# M051DE_v1 register map
File version: 1.0
Registers are 32-bit, read-write, reset 0x0 unless marked. A register's access mark holds for its fields unless they carry their own. Offsets are from the block's base; [hi:lo] are bit positions; lines under a group give offsets from that group; {n}, {i} and the like mark numbered series; 'fields as' and 'values as' point back to an identical list.

## PWMA — PWM Register Map
Base 0x40040000
Same registers: PWMB 0x40140000
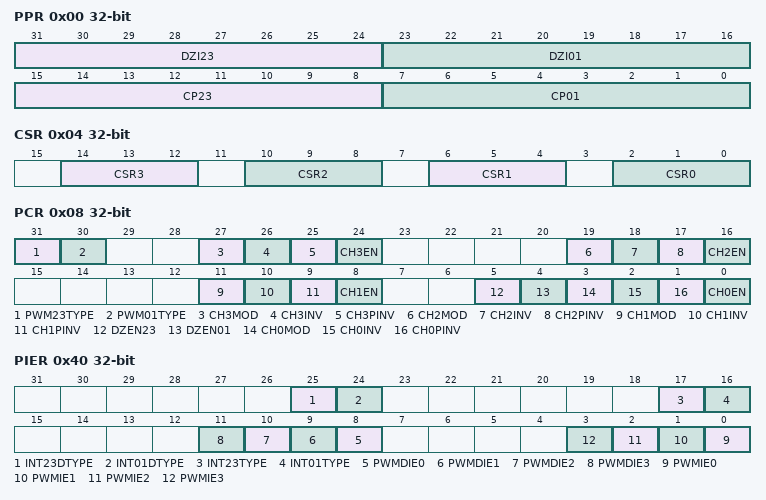
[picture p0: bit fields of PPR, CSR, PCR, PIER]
0x00 PPR — PWM Prescaler Register
  [31:24] DZI23 — Dead-zone Interval for Pair of Channel 2 and Channel 3 (PWM2 and PWM3 Pair for PWM Group A, PWM6 and PWM7 Pair for PWM Group B). These 8-bit determine the Dead-zone length.
  [23:16] DZI01 — Dead-zone Interval for Pair of Channel 0 and Channel 1 (PWM0 and PWM1 Pair for PWM Group A, PWM4 and PWM5 Pair for PWM Group B). These 8-bit determine the Dead-zone length.
  [15:8] CP23 — Clock Prescaler 2 (PWM-timer 2 / 3 for Group A and PWM-timer 6 / 7 for Group B). Clock input is divided by (CP23 + 1) before it is fed to the corresponding PWM-Timer.
  [7:0] CP01 — Clock Prescaler 0 (PWM-timer 0 / 1 for Group A and PWM-timer 4 / 5 for Group B). Clock input is divided by (CP01 + 1) before it is fed to the corresponding PWM-Timer
0x04 CSR — PWM Clock Source Divider Select Register
  [14:12] CSR3 — PWM Timer 3 Clock Source Divider Selection (PWM Timer 3 for Group A and PWM Timer 7 for Group B)
  [10:8] CSR2 — PWM Timer 2 Clock Source Divider Selection (PWM Timer 2 for Group A and PWM Timer 6 for Group B). Select clock source divider for PWM timer 2. (Table is the same as CSR3)
  [6:4] CSR1 — PWM Timer 1 Clock Source Divider Selection (PWM Timer 1 for Group A and PWM Timer 5 for Group B). Select clock source divider for PWM timer 1. (Table is the same as CSR3)
  [2:0] CSR0 — PWM Timer 0 Clock Source Divider Selection (PWM Timer 0 for Group A and PWM Timer 4 for Group B). Select clock source divider for PWM timer 0. (Table is the same as CSR3)
0x08 PCR — PWM Control Register
  [31] PWM23TYPE — PWM23 Aligned Type Selection Bit (PWM2 and PWM3 Pair for PWM Group A, PWM6 and PWM7 Pair for PWM Group B) (M05xxDN/DE Only)
    0=Edge-aligned type; 1=Center-aligned type
  [30] PWM01TYPE — PWM01 Aligned Type Selection Bit (PWM0 and PWM1 Pair for PWM Group A, PWM4 and PWM5 Pair for PWM Group B) (M05xxDN/DE Only)
    0=Edge-aligned type; 1=Center-aligned type
  [27] CH3MOD — PWM-timer 3 Auto-reload/One-shot Mode Control (PWM Timer 3 for Group A and PWM Timer 7 for Group B). Note: If there is a transition at this bit, it will cause CNR3 and CMR3 be cleared.
    0=One-shot mode; 1=Auto-reload mode
  [26] CH3INV — PWM-timer 3 Output Inverter Enable Control (PWM Timer 3 for Group A and PWM Timer 7 for Group B)
    0=Inverter Disabled; 1=Inverter Enabled
  [25] CH3PINV — PWM-timer 3 Output Polar Inverse Enable Control (PWM Timer 3 for Group A and PWM Timer 7 for Group B) (M05xxDN/DE Only)
    0=Polar Inverter Disabled; 1=Polar Inverter Enabled
  [24] CH3EN — PWM-timer 3 Enable Control (PWM Timer 3 for Group A and PWM Timer 7 for Group B)
    0=Corresponding PWM-Timer Stopped; 1=Corresponding PWM-Timer Start Running
  [19] CH2MOD — PWM-timer 2 Auto-reload/One-shot Mode Control (PWM Timer 2 for Group A and PWM Timer 6 for Group B). Note: If there is a transition at this bit, it will cause CNR2 and CMR2 be cleared.
    0=One-shot mode; 1=Auto-reload mode
  [18] CH2INV — PWM-timer 2 Output Inverter Enable Control (PWM Timer 2 for Group A and PWM Timer 6 for Group B)
    0=Inverter Disabled; 1=Inverter Enabled
  [17] CH2PINV — PWM-timer 2 Output Polar Inverse Enable (PWM Timer 2 for Group A and PWM Timer 6 for Group B) (M05xxDN/DE Only)
    0=Polar Inverter Disabled; 1=Polar Inverter Enabled
  [16] CH2EN — PWM-timer 2 Enable (PWM Timer 2 for Group A and PWM Timer 6 for Group B)
    values as CH3EN
  [11] CH1MOD — PWM-timer 1 Auto-reload/One-shot Mode (PWM Timer 1 for Group A and PWM Timer 5 for Group B). Note: If there is a transition at this bit, it will cause CNR1 and CMR1 be cleared.
    0=One-shot mode; 1=Auto-reload mode
  [10] CH1INV — PWM-timer 1 Output Inverter Enable (PWM Timer 1 for Group A and PWM Timer 5 for Group B)
    0=Inverter Disabled; 1=Inverter Enabled
  [9] CH1PINV — PWM-timer 1 Output Polar Inverse Enable (PWM Timer 1 for Group A and PWM Timer 5 for Group B) (M05xxDN/DE Only)
    0=Polar Inverter Disabled; 1=Polar Inverter Enabled
  [8] CH1EN — PWM-timer 1 Enable (PWM Timer 1 for Group A and PWM Timer 5 for Group B)
    values as CH3EN
  [5] DZEN23 — Dead-zone 2 Generator Enable (PWM2 and PWM3 Pair for PWM Group A, PWM6 and PWM7 Pair for PWM Group B). Note: When Dead-zone generator is enabled, the pair of PWM2 and PWM3 becomes a complementary pair for PWM group A and the pair of PWM6 and PWM7 becomes a complementary pair for PWM group B.
    0=Disabled; 1=Enabled
  [4] DZEN01 — Dead-zone 0 Generator Enable Control (PWM0 and PWM1 Pair for PWM Group A, PWM4 and PWM5 Pair for PWM Group B). Note: When Dead-zone generator is enabled, the pair of PWM0 and PWM1 becomes a complementary pair for PWM group A and the pair of PWM4 and PWM5 becomes a complementary pair for PWM group B.
    0=Disabled; 1=Enabled
  [3] CH0MOD — PWM-timer 0 Auto-reload/One-shot Mode Control (PWM Timer 0 for Group A and PWM Timer 4 for Group B). Note: If there is a transition at this bit, it will cause CNR0 and CMR0 be cleared.
    0=One-shot mode; 1=Auto-reload mode
  [2] CH0INV — PWM-timer 0 Output Inverter Enable Control (PWM Timer 0 for Group A and PWM Timer 4 for Group B)
    0=Inverter Disabled; 1=Inverter Enabled
  [1] CH0PINV — PWM-timer 0 Output Polar Inverse Enable Control (PWM Timer 0 for Group A and PWM Timer 4 for Group B) (M05xxDN/DE Only)
    0=Polar Inverter Disabled; 1=Polar Inverter Enabled
  [0] CH0EN — PWM-timer 0 Enable Control (PWM Timer 0 for Group A and PWM Timer 4 for Group B)
    0=The corresponding PWM-Timer stops running; 1=The corresponding PWM-Timer starts running
{0xC+0xC*i} CNR{i} (i=0..3) — PWM Counter Register {i}
  [15:0] CNRx — PWM Timer Loaded Value. CNR determines the PWM period. Note1: Any write operation to CNR will take effect in next PWM cycle. Note2: When CNR value is set to 0, PWM output is always high. Note3: When PWM operating at center-aligned type, CNR value should be set between 0x0001 to 0xFFFE. If CNR equal to 0x0000 or 0xFFFF, the PWM will work unpredictable.
{0x10+0xC*i} CMR{i} (i=0..3) — PWM Comparator Register {i}
  [15:0] CMRx — PWM Comparator Register. CMR determines the PWM duty. Note: Any write operation to CMR will take effect in next PWM cycle.
{0x14+0xC*i} PDR{i} ro (i=0..3) — PWM Data Register {i}
  [15:0] PDRx — PWM Data Register. User can monitor PDR to know the current value in 16-bit counter.
0x40 PIER — PWM Interrupt Enable Register
  [25] INT23DTYPE — PWM23 Duty Interrupt Type Selection (PWM2 and PWM3 Pair for PWM Group A, PWM6 and PWM7 Pair for PWM Group B) (M05xxDN/DE Only). Note: Set INT23DTYPE to 1 only work when PWM operating in center aligned type.
    0=PWMDIFx will be set if PWM counter down count and matches CMRx register. PWM will trigger ADC to conversion when PWM counter down count and matches CMRx register if correlate PWM trigger enable bit (PWMxDTEN) is set to 1; 1=PWMDIFx will be set when PWM counter up count and matches CMRx register. PWM will trigger ADC to conversion when PWM counter up count and matches CMRx register if correlate PWM trigger enable bit (PWMxDTEN) is set to 1
  [24] INT01DTYPE — PWM01 Duty Interrupt Type Selection (PWM0 and PWM1 Pair for PWM Group A, PWM4 and PWM5 Pair for PWM Group B) (M05xxDN/DE Only). Note: Set INT01DTYPE to 1 only work when PWM operating in center aligned type.
    values as INT23DTYPE
  [17] INT23TYPE — PWM23 Interrupt Period Type Selection (PWM2 and PWM3 Pair for PWM Group A, PWM6 and PWM7 Pair for PWM Group B) (M05xxDN/DE Only). Note: Setting INT23TYPE to 1 only works when PWM operating is in center-aligned type.
    0=PWMIFx will be set if PWM counter underflow. PWM will trigger ADC to conversion when PWM counter underflow if correlate PWM trigger enable bit (PWMxTEN) is set to 1; 1=PWMIFx will be set if PWM counter matches CNRx register. PWM will trigger ADC to conversion when PWM counter matches CNRx register if correlate PWM trigger enable bit (PWMxTEN) is set to 1
  [16] INT01TYPE — PWM01 Interrupt Period Type Selection (PWM0 and PWM1 Pair for PWM Group A, PWM4 and PWM5 Pair for PWM Group B) (M05xxDN/DE Only). Note: Setting INT01TYPE to 1 only works when PWM operating is in center-aligned type.
    values as INT23TYPE
  [n+8] PWMDIE{n} (n=0..3) — PWM Channel {n} Duty Interrupt Enable Control (M05xxDN/DE Only)
    0=PWM channel {n} duty interrupt Disabled; 1=PWM channel {n} duty interrupt Enabled
  [n] PWMIE{n} (n=0..3) — PWM Channel {n} Period Interrupt Enable Control
    0=PWM channel {n} period interrupt Disabled; 1=PWM channel {n} period interrupt Enabled
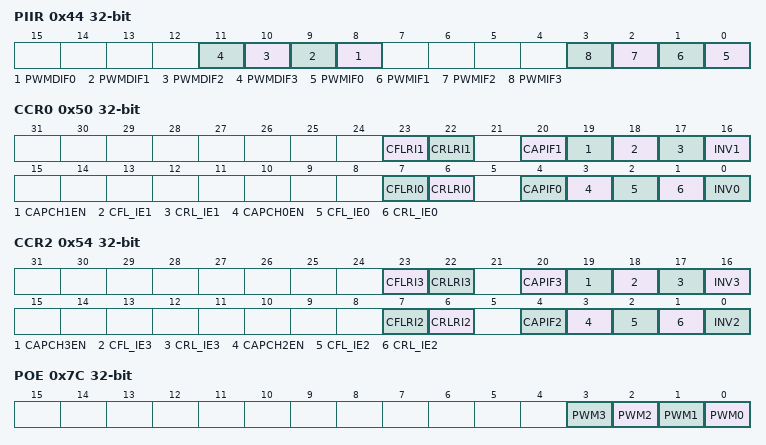
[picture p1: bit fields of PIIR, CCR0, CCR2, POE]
0x44 PIIR — PWM Interrupt Indication Register
  [n+8] PWMDIF{n} (n=0..3) — PWM Channel {n} Duty Interrupt Status (M05xxDN/DE Only). Note: Write 1 to clear this bit to 0.
  [n] PWMIF{n} (n=0..3) — PWM Channel {n} Period Interrupt Status. On M05xxBN: This bit is set by hardware when channel {n} PWM counter equal to zero if channel {n} PWM period interrupt enable bit (PWMIE{n}) is 1. Software can write 1 to clear this bit to 0. On M05xxDN/DE: Note: Write 1 to clear this bit to 0.
0x50 CCR0 — PWM Capture Control Register 0
  [23] CFLRI1 — CFLR1 Latched Indicator. When PWM group input channel 1 has a falling transition, CFLR1 was latched with the value of PWM down-counter and this bit is set by hardware. Note: Write 1 to clear this bit to 0.
  [22] CRLRI1 — CRLR1 Latched Indicator. When PWM group input channel 1 has a rising transition, CRLR1 was latched with the value of PWM down-counter and this bit is set by hardware. Note: Write 1 to clear this bit to 0.
  [20] CAPIF1 — Channel 1 Capture Interrupt Indication Flag. Note: Write 1 to clear this bit to 0.
  [19] CAPCH1EN — Channel 1 Capture Function Enable Control. Note1: When Enabled, Capture latched the PWM-counter and saved to CRLR (Rising latch) and CFLR (Falling latch). Note2: When Disabled, Capture does not update CRLR and CFLR, and disable PWM group channel 1 Interrupt.
    0=Capture function on PWM group channel 1 Disabled; 1=Capture function on PWM group channel 1 Enabled
  [18] CFL_IE1 — Channel 1 Falling Latch Interrupt Enable Control. Note: When Enabled, if Capture detects PWM group channel 1 has falling transition, Capture will issue an Interrupt.
    0=Falling latch interrupt Disabled; 1=Falling latch interrupt Enabled
  [17] CRL_IE1 — Channel 1 Rising Latch Interrupt Enable Control. Note: When Enabled, if Capture detects PWM group channel 1 has rising transition, Capture will issue an Interrupt.
    0=Rising latch interrupt Disabled; 1=Rising latch interrupt Enabled
  [16] INV1 — Capture Channel 1 Inverter Enable Control
    0=Inverter Disabled; 1=Inverter Enabled. Reverse the input signal from GPIO before fed to Capture timer
  [7] CFLRI0 — CFLR0 Latched Indicator Control. When PWM group input channel 0 has a falling transition, CFLR0 was latched with the value of PWM down-counter and this bit is set by hardware. Note: Write 1 to clear this bit to 0.
  [6] CRLRI0 — CRLR0 Latched Indicator. When PWM group input channel 0 has a rising transition, CRLR0 was latched with the value of PWM down-counter and this bit is set by hardware. Note: Write 1 to clear this bit to 0.
  [4] CAPIF0 — Channel 0 Capture Interrupt Indication Flag. Note: Write 1 to clear this bit to 0.
  [3] CAPCH0EN — Channel 0 Capture Function Enable Control. Note1: When Enabled, Capture latches the PWM-counter value and saved to CRLR (Rising latch) and CFLR (Falling latch). Note2: When Disabled, Capture does not update CRLR and CFLR, and disable PWM group channel 0 Interrupt.
    0=Capture function on PWM group channel 0 Disabled; 1=Capture function on PWM group channel 0 Enabled
  [2] CFL_IE0 — Channel 0 Falling Latch Interrupt Enable Control. Note: When Enabled, if Capture detects PWM group channel 0 has falling transition, and Capture will issue an Interrupt.
    values as CFL_IE1
  [1] CRL_IE0 — Channel 0 Rising Latch Interrupt Enable Control. Note: When Enabled, if Capture detects PWM group channel 0 has rising transition, Capture will issue an Interrupt.
    values as CRL_IE1
  [0] INV0 — Capture Channel 0 Inverter Enable Control
    values as INV1
0x54 CCR2 — PWM Capture Control Register 2
  [23] CFLRI3 — CFLR3 Latched Indicator. When PWM group input channel 3 has a falling transition, CFLR3 was latched with the value of PWM down-counter and this bit is set by hardware. Note: Write 1 to clear this bit to 0.
  [22] CRLRI3 — CRLR3 Latched Indicator. When PWM group input channel 3 has a rising transition, CRLR3 was latched with the value of PWM down-counter and this bit is set by hardware. Note: Write 1 to clear this bit to 0.
  [20] CAPIF3 — Channel 3 Capture Interrupt Indication Flag. Note: Write 1 to clear this bit to 0.
  [19] CAPCH3EN — Channel 3 Capture Function Enable Control. Note1: When Enabled, Capture latched the PWM-counter and saved to CRLR (Rising latch) and CFLR (Falling latch). Note2: When Disabled, Capture does not update CRLR and CFLR, and disable PWM group channel 3 Interrupt.
    0=Capture function on PWM group channel 3 Disabled; 1=Capture function on PWM group channel 3 Enabled
  [18] CFL_IE3 — Channel 3 Falling Latch Interrupt Enable Control. Note: When Enabled, if Capture detects PWM group channel 3 has falling transition, Capture will issue an Interrupt.
    values as CCR0.CFL_IE1
  [17] CRL_IE3 — Channel 3 Rising Latch Interrupt Enable Control. Note: When Enabled, if Capture detects PWM group channel 3 has rising transition, Capture will issue an Interrupt.
    values as CCR0.CRL_IE1
  [16] INV3 — Capture Channel 3 Inverter Enable Control
    values as CCR0.INV1
  [7] CFLRI2 — CFLR2 Latched Indicator. When PWM group input channel 2 has a falling transition, CFLR2 was latched with the value of PWM down-counter and this bit is set by hardware. Note: Write 1 to clear this bit to 0.
  [6] CRLRI2 — CRLR2 Latched Indicator. When PWM group input channel 2 has a rising transition, CRLR2 was latched with the value of PWM down-counter and this bit is set by hardware. Note: Write 1 to clear this bit to 0.
  [4] CAPIF2 — Channel 2 Capture Interrupt Indication Flag. Note: Write 1 to clear this bit to 0.
  [3] CAPCH2EN — Channel 2 Capture Function Enable Control. Note1: When Enabled, Capture latched the PWM-counter value and saved to CRLR (Rising latch) and CFLR (Falling latch). Note2: When Disabled, Capture does not update CRLR and CFLR, and disable PWM group channel 2 Interrupt.
    0=Capture function on PWM group channel 2 Disabled; 1=Capture function on PWM group channel 2 Enabled
  [2] CFL_IE2 — Channel 2 Falling Latch Interrupt Enable Control. Note: When Enabled, if Capture detects PWM group channel 2 has falling transition, Capture will issue an Interrupt.
    values as CCR0.CFL_IE1
  [1] CRL_IE2 — Channel 2 Rising Latch Interrupt Enable Control. Note: When Enabled, if Capture detects PWM group channel 2 has rising transition, Capture will issue an Interrupt.
    values as CCR0.CRL_IE1
  [0] INV2 — Capture Channel 2 Inverter Enable Control
    values as CCR0.INV1
{0x58+8i} CRLR{i} ro (i=0..3) — PWM Capture Rising Latch Register (Channel {i})
  [15:0] CRLRx — Capture Rising Latch Register. Latch the PWM counter value when Channel 0/1/2/3 has rising transition.
{0x5C+8i} CFLR{i} ro (i=0..3) — PWM Capture Falling Latch Register (Channel {i})
  [15:0] CFLRx — Capture Falling Latch Register. Latch the PWM counter value when Channel 0/1/2/3 has Falling transition.
0x78 CAPENR — PWM Capture Input 0~3 Enable Register
  [3:0] CAPENR — Capture Input Enable Register. CAPENR. Bit 3210 for PWM group A. Bit xxx1 ( Capture channel 0 enabled. Capture input channel can be from P2.0 or P4.0. User can only select one of pins by setting multi-function pin register. Bit xx1x ( Capture channel 1 enabled. Capture input channel can be from P2.1 or P4.1. User can only select one of pins by setting multi-function pin register. Bit x1xx ( Capture channel 2 enabled. Capture input channel can be from P2.2 or P4.2. User can only select one of pins by setting multi-function pin register. Bit 1xxx ( Capture channel 3 enabled. Capture input channel can be from P2.3 or P4.3. User can only select one of pins by setting multi-function pin register. Bit 3210 for PWM group B. Bit xxx1 ( Capture channel 0 enabled. Capture input channel can be from P2.4 by setting multi-function pin register. Bit xx1x ( Capture channel 1 enabled. Capture input channel can be from P2.5 by setting multi-function pin register. Bit x1xx ( Capture channel 2 enabled. Capture input channel can be from P2.6 by setting multi-function pin register. Bit 1xxx ( Capture channel 3 enabled. Capture input channel can be from P2.7 by setting multi-function pin register.
    0=Capture input Disabled. (PWMx multi-function pin input does not affect input capture function.); 1=Capture input Enabled. (PWMx multi-function pin input will affect its input capture function.)
0x7C POE — PWM Output Enable Register for Channel 0~3
  [n] PWM{n} (n=0..3) — Channel {n} Output Enable Register. Note: The corresponding GPIO pin must also be switched to PWM function.
    0=PWM channel {n} output to pin Disabled; 1=PWM channel {n} output to pin Enabled
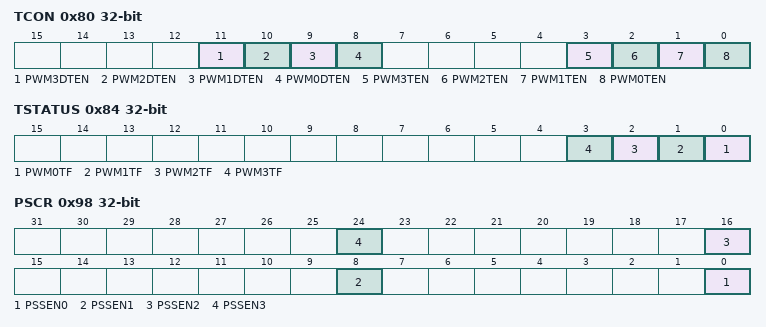
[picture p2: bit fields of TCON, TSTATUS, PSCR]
0x80 TCON — PWM Trigger Control Register for Channel 0~3 (M05xxDN/DE Only)
  [11] PWM3DTEN — Channel 3 PWM Duty Trigger ADC Enable Control (M05xxDN/DE Only). As PWM operating at edge-aligned type, enable this bit can make PWM trigger ADC to start conversion when PWM channel 3 counter down count to match CMR3. As PWM operating at center-aligned type, enable this bit can make PWM trigger ADC to start conversion when PWM channel 3 counter up count or down count to match CMR3 based on INT23DTYPE setting.
    0=PWM channel 3 duty trigger ADC function Disabled; 1=PWM channel 3 duty trigger ADC function Enabled
  [10] PWM2DTEN — Channel 2 PWM Duty Trigger ADC Enable Control (M05xxDN/DE Only). As PWM operating at edge-aligned type, enable this bit can make PWM trigger ADC to start conversion when PWM channel 2 counter down count to match CMR2. As PWM operating at center-aligned type, enable this bit can make PWM trigger ADC to start conversion when PWM channel 2 counter up count or down count to match CMR2 based on INT23DTYPE setting.
    0=PWM channel 2 duty trigger ADC function Disabled; 1=PWM channel 2 duty trigger ADC function Enabled
  [9] PWM1DTEN — Channel 1 PWM Duty Trigger ADC Enable Control (M05xxDN/DE Only). As PWM operating at edge-aligned type, enable this bit can make PWM trigger ADC to start conversion when PWM channel 1 counter down count to match CMR1. As PWM operating at center-aligned type, enable this bit can make PWM trigger ADC to start conversion when PWM channel 1 counter up count or down count to match CMR1 based on INT01DTYPE setting.
    0=PWM channel 1 duty trigger ADC function Disabled; 1=PWM channel 1 duty trigger ADC function Enabled
  [8] PWM0DTEN — Channel 0 PWM Duty Trigger ADC Enable Control (M05xxDN/DE Only). As PWM operating at edge-aligned type, enable this bit can make PWM trigger ADC to start conversion when PWM channel 0 counter down count to match CMR0. As PWM operating at center-aligned type, enable this bit can make PWM trigger ADC to start conversion when PWM channel 0 counter up count or down count to match CMR0 based on INT01DTYPE setting.
    0=PWM channel 0 duty trigger ADC function Disabled; 1=PWM channel 0 duty trigger ADC function Enabled
  [3] PWM3TEN — Channel 3 PWM Period Trigger ADC Enable Control (M05xxDN/DE Only). As PWM operating at edge-aligned type, enable this bit can make PWM trigger ADC to start conversion when PWM channel 3 counter down count to underflow. As PWM operating at center-aligned type, enable this bit can make PWM trigger ADC to start conversion when PWM channel 3 counter up count to (CNR3 + 1) or down count to underflow based on INT23PTYPE setting.
    0=PWM channel 3 period trigger ADC function Disabled; 1=PWM channel 3 period trigger ADC function Enabled
  [2] PWM2TEN — Channel 2 PWM Period Trigger ADC Enable Control (M05xxDN/DE Only). As PWM operating at edge-aligned type, enable this bit can make PWM trigger ADC to start conversion when PWM channel 2 counter down count to underflow. As PWM operating at center-aligned type, enable this bit can make PWM trigger ADC to start conversion when PWM channel 2 counter up count to (CNR2 + 1) or down count to underflow based on INT23PTYPE setting.
    0=PWM channel 2 period trigger ADC function Disabled; 1=PWM channel 2 period trigger ADC function Enabled
  [1] PWM1TEN — Channel 1 PWM Period Trigger ADC Enable Control (M05xxDN/DE Only). As PWM operating at edge-aligned type, enable this bit can make PWM trigger ADC to start conversion when PWM channel 1 counter down count to underflow. As PWM operating at center-aligned type, enable this bit can make PWM trigger ADC to start conversion when PWM channel 1 counter up count to (CNR1 + 1) or down count to underflow based on INT01PTYPE setting.
    0=PWM channel 1 period trigger ADC function Disabled; 1=PWM channel 1 period trigger ADC function Enabled
  [0] PWM0TEN — Channel 0 PWM Period Trigger ADC Enable Control (M05xxDN/DE Only). As PWM operating at edge-aligned type, enable this bit can make PWM trigger ADC to start conversion when PWM channel 0 counter down count to underflow. As PWM operating at center-aligned type, enable this bit can make PWM trigger ADC to start conversion when PWM channel 0 counter up count to (CNR0 + 1) or down count to underflow based on INT01PTYPE setting.
    0=PWM channel 0 period trigger ADC function Disabled; 1=PWM channel 0 period trigger ADC function Enabled
0x84 TSTATUS — PWM Trigger Status Register (M05xxDN/DE Only)
  [n] PWM{n}TF (n=0..3) — Channel {n} PWM Trigger ADC Flag (M05xxDN/DE Only). This bit is set to 1 by hardware when PWM channel {n} trigger ADC condition matched. ADC will start conversion if ADC triggered source is selected by PWM while this bit is set to 1. Note: Write 1 to clear this bit to 0.
0x98 PSCR — PWM Synchronous Control Register (M05xxDN/DE Only)
  [8n] PSSEN{n} (n=0..3) — Channel {n} PWM-timer Synchronous Start Enable Control (M05xxDN/DE Only). If this bit is set to 1, the PWM-Timer channel {n} of specified PWM group will synchronously start with PWM-Timer channel 0 of PWM group A when SW writes 1 to CH0EN(PCR[0]) in PWM group A.
    0=Channel {n} PWM-Timer Synchronous Start Disabled; 1=Channel {n} PWM-Timer Synchronous Start Enabled
